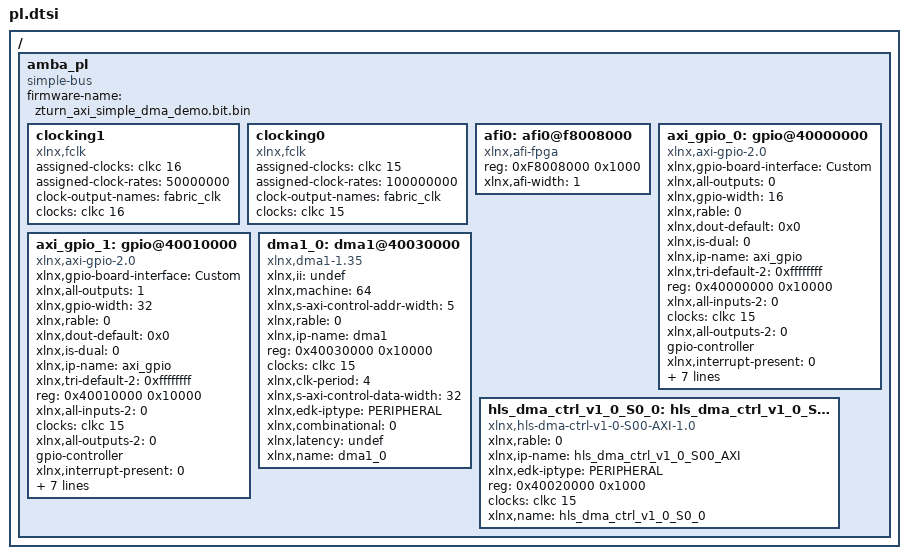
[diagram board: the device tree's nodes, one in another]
/ {
	amba_pl: amba_pl {
		ranges;
		compatible = "simple-bus";
		#address-cells = <1>;
		#size-cells = <1>;
		firmware-name = "zturn_axi_simple_dma_demo.bit.bin";
		clocking1: clocking1 {
			compatible = "xlnx,fclk";
			assigned-clocks = <&clkc 16>;
			assigned-clock-rates = <50000000>;
			#clock-cells = <0>;
			clock-output-names = "fabric_clk";
			clocks = <&clkc 16>;
		};
		clocking0: clocking0 {
			compatible = "xlnx,fclk";
			assigned-clocks = <&clkc 15>;
			assigned-clock-rates = <100000000>;
			#clock-cells = <0>;
			clock-output-names = "fabric_clk";
			clocks = <&clkc 15>;
		};
		afi0: afi0@f8008000 {
			status = "okay";
			compatible = "xlnx,afi-fpga";
			#address-cells = <1>;
			reg = <0xF8008000 0x1000>;
			#size-cells = <0>;
			xlnx,afi-width = <1>;
		};
		axi_gpio_0: gpio@40000000 {
			xlnx,gpio-board-interface = "Custom";
			compatible = "xlnx,axi-gpio-2.0" , "xlnx,xps-gpio-1.00.a";
			xlnx,all-outputs = <0>;
			#gpio-cells = <2>;
			xlnx,gpio-width = <16>;
			xlnx,rable = <0>;
			xlnx,dout-default = <0x0>;
			xlnx,is-dual = <0>;
			xlnx,ip-name = "axi_gpio";
			xlnx,tri-default-2 = <0xffffffff>;
			reg = <0x40000000 0x10000>;
			xlnx,all-inputs-2 = <0>;
			clocks = <&clkc 15>;
			xlnx,all-outputs-2 = <0>;
			gpio-controller;
			xlnx,interrupt-present = <0>;
			xlnx,gpio2-board-interface = "Custom";
			xlnx,edk-iptype = "PERIPHERAL";
			xlnx,dout-default-2 = <0x0>;
			status = "okay";
			xlnx,gpio2-width = <32>;
			clock-names = "s_axi_aclk";
			xlnx,tri-default = <0xffffffff>;
			xlnx,name = "axi_gpio_0";
			xlnx,all-inputs = <1>;
		};
		axi_gpio_1: gpio@40010000 {
			xlnx,gpio-board-interface = "Custom";
			compatible = "xlnx,axi-gpio-2.0" , "xlnx,xps-gpio-1.00.a";
			xlnx,all-outputs = <1>;
			#gpio-cells = <2>;
			xlnx,gpio-width = <32>;
			xlnx,rable = <0>;
			xlnx,dout-default = <0x0>;
			xlnx,is-dual = <0>;
			xlnx,ip-name = "axi_gpio";
			xlnx,tri-default-2 = <0xffffffff>;
			reg = <0x40010000 0x10000>;
			xlnx,all-inputs-2 = <0>;
			clocks = <&clkc 15>;
			xlnx,all-outputs-2 = <0>;
			gpio-controller;
			xlnx,interrupt-present = <0>;
			xlnx,gpio2-board-interface = "Custom";
			xlnx,edk-iptype = "PERIPHERAL";
			xlnx,dout-default-2 = <0x0>;
			status = "okay";
			xlnx,gpio2-width = <32>;
			clock-names = "s_axi_aclk";
			xlnx,tri-default = <0xffffffff>;
			xlnx,name = "axi_gpio_1";
			xlnx,all-inputs = <0>;
		};
		dma1_0: dma1@40030000 {
			compatible = "xlnx,dma1-1.35";
			xlnx,ii = "undef";
			xlnx,machine = <64>;
			xlnx,s-axi-control-addr-width = <5>;
			xlnx,rable = <0>;
			xlnx,ip-name = "dma1";
			reg = <0x40030000 0x10000>;
			clocks = <&clkc 15>;
			xlnx,clk-period = <4>;
			xlnx,s-axi-control-data-width = <32>;
			xlnx,edk-iptype = "PERIPHERAL";
			status = "okay";
			clock-names = "ap_clk";
			xlnx,combinational = <0>;
			xlnx,latency = "undef";
			xlnx,name = "dma1_0";
		};
		hls_dma_ctrl_v1_0_S0_0: hls_dma_ctrl_v1_0_S00_AXI@40020000 {
			xlnx,rable = <0>;
			compatible = "xlnx,hls-dma-ctrl-v1-0-S00-AXI-1.0";
			status = "okay";
			clock-names = "S_AXI_ACLK";
			xlnx,ip-name = "hls_dma_ctrl_v1_0_S00_AXI";
			xlnx,edk-iptype = "PERIPHERAL";
			reg = <0x40020000 0x1000>;
			clocks = <&clkc 15>;
			xlnx,name = "hls_dma_ctrl_v1_0_S0_0";
		};
	};
};
